VERSION ""

NS_ :

BS_:

BU_: SENSOR_NODE LOGGER

BO_ 256 FLOW1: 8 SENSOR_NODE
 SG_ rate_lpm_1 : 7|16@0+ (0.01,0) [0|300] "L/min" LOGGER
 SG_ total_volume_l_1 : 23|32@0+ (0.001,0) [0|4294967.295] "L" LOGGER

BO_ 257 FLOW2: 8 SENSOR_NODE
 SG_ rate_lpm_2 : 7|16@0+ (0.01,0) [0|300] "L/min" LOGGER
 SG_ total_volume_l_2 : 23|32@0+ (0.001,0) [0|4294967.295] "L" LOGGER

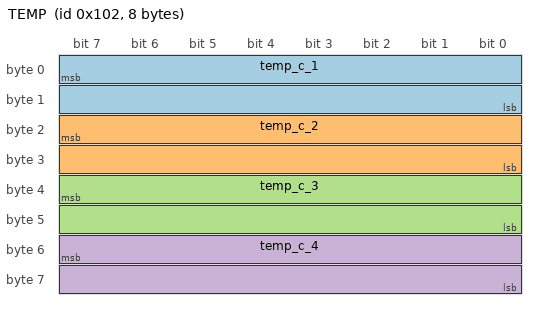
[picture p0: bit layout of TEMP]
BO_ 258 TEMP: 8 SENSOR_NODE
 SG_ temp_c_1 : 7|16@0- (0.01,0) [-40|200] "degC" LOGGER
 SG_ temp_c_2 : 23|16@0- (0.01,0) [-40|200] "degC" LOGGER
 SG_ temp_c_3 : 39|16@0- (0.01,0) [-40|200] "degC" LOGGER
 SG_ temp_c_4 : 55|16@0- (0.01,0) [-40|200] "degC" LOGGER

CM_ "Local DBC for cooling_system sensor node only. Temporary - IDs/layout are
placeholders until migrated into the global DBC. See AGENTS.md.";
CM_ BO_ 256 "Flow channel 1: rate + cumulative total volume.";
CM_ BO_ 257 "Flow channel 2: rate + cumulative total volume.";
CM_ BO_ 258 "Analog channels 1-4 as NTC temperature.";

BA_DEF_ BO_ "GenMsgCycleTime" INT 0 100000;
BA_DEF_DEF_ "GenMsgCycleTime" 0;
BA_ "GenMsgCycleTime" BO_ 256 100;
BA_ "GenMsgCycleTime" BO_ 257 100;
BA_ "GenMsgCycleTime" BO_ 258 500;
